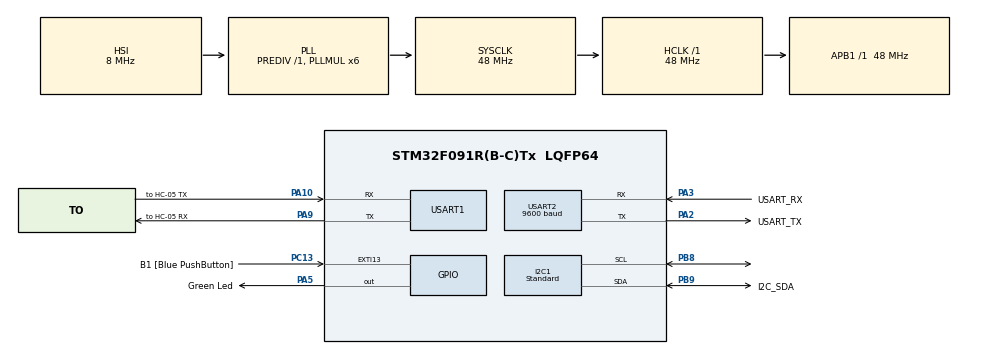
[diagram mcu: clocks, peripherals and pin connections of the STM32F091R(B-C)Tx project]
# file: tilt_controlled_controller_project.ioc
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I2C1.I2C_Speed_Mode=I2C_Standard
Mcu.Family=STM32F0
Mcu.Name=STM32F091R(B-C)Tx
Mcu.Package=LQFP64
NVIC.EXTI4_15_IRQn=true\:0\:0\:false\:false\:true\:true\:true\:true
NVIC.USART2_IRQn=true\:0\:0\:false\:false\:true\:true\:true\:true
PA10.GPIO_Label=to HC-05 TX
PA10.Mode=Asynchronous
PA10.Signal=USART1_RX
PA13.GPIO_Label=TMS
PA13.Mode=Serial_Wire
PA13.Signal=SYS_SWDIO
PA14.GPIO_Label=TCK
PA14.Mode=Serial_Wire
PA14.Signal=SYS_SWCLK
PA2.GPIO_Label=USART_TX
PA2.GPIO_Mode=GPIO_MODE_AF_PP
PA2.GPIO_PuPd=GPIO_NOPULL
PA2.GPIO_Speed=GPIO_SPEED_FREQ_LOW
PA2.Mode=Asynchronous
PA2.Signal=USART2_TX
PA3.GPIO_Label=USART_RX
PA3.GPIO_Mode=GPIO_MODE_AF_PP
PA3.GPIO_PuPd=GPIO_NOPULL
PA3.GPIO_Speed=GPIO_SPEED_FREQ_LOW
PA3.Mode=Asynchronous
PA3.Signal=USART2_RX
PA5.GPIO_Label=Green Led
PA5.GPIO_Mode=GPIO_MODE_OUTPUT_PP
PA5.GPIO_PuPd=GPIO_NOPULL
PA5.GPIO_Speed=GPIO_SPEED_FREQ_LOW
PA5.Signal=GPIO_Output
PA9.GPIO_Label=to HC-05 RX
PA9.Mode=Asynchronous
PA9.Signal=USART1_TX
PB8.Mode=I2C
PB8.Signal=I2C1_SCL
PB9.GPIO_Label=I2C_SDA
PB9.Mode=I2C
PB9.Signal=I2C1_SDA
PC13.GPIO_Label=B1 [Blue PushButton]
PC13.GPIO_ModeDefaultEXTI=GPIO_MODE_IT_FALLING
PC13.Signal=GPXTI13
PC14OSC32_IN.Mode=LSE-External-Oscillator
PC14OSC32_IN.Signal=RCC_OSC32_IN
PC15OSC32_OUT.Mode=LSE-External-Oscillator
PC15OSC32_OUT.Signal=RCC_OSC32_OUT
PF0-OSC_IN.Mode=HSE-External-Clock-Source
PF0-OSC_IN.Signal=RCC_OSC_IN
PF1-OSC_OUT.Signal=RCC_OSC_OUT
ProjectManager.HeapSize=0x200
ProjectManager.StackSize=0x400
ProjectManager.TargetToolchain=STM32CubeIDE
RCC.AHBFreq_Value=48000000
RCC.APB1Freq_Value=48000000
RCC.APB1TimFreq_Value=48000000
RCC.FLatency-AdvancedSettings=FLASH_LATENCY_1
RCC.HCLKFreq_Value=48000000
RCC.PLLMUL=RCC_PLL_MUL6
RCC.PREFETCH_ENABLE-AdvancedSettings=1
RCC.SYSCLKFreq_VALUE=48000000
RCC.SYSCLKSource=RCC_SYSCLKSOURCE_PLLCLK
USART1.VirtualMode-Asynchronous=VM_ASYNC
USART2.BaudRate=9600
USART2.VirtualMode=VM_ASYNC
USART2.VirtualMode-Asynchronous=VM_ASYNC
board=NUCLEO-F091RC

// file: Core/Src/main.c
/* USER CODE BEGIN Header */
/**
  ******************************************************************************
  * @file   main.c
  * @brief  Main program body
  * @author Anil Ozrenk
  ******************************************************************************
  * @attention
  *
  * Copyright (c) 2022 Anil Ozrenk.
  * All rights reserved.
  *
  * This software is licensed under terms that can be found in the LICENSE file
  * in the root directory of this software component.
  * If no LICENSE file comes with this software, it is provided AS-IS.
  *
  ******************************************************************************
  */
/* USER CODE END Header */
#include "main.h"

/* USER CODE BEGIN Includes */
#include "mpu6050.h"
#include "controller.h"
/* USER CODE END Includes */

/* USER CODE BEGIN PD */
#define BUFFER_LEN  13 ///< predefined lenght to main uart buffer
#define KF 0.85  	   ///< exponantial filter coeficient
/* USER CODE END PD */

I2C_HandleTypeDef hi2c1;
UART_HandleTypeDef huart1;
UART_HandleTypeDef huart2;

/* USER CODE BEGIN PV */

MPU6050_t MPU6050;
typHoverHandler hHover;
typPWMInputHandler hInput;
typPWMOutputHandler hOutput;
typVector hVector;

/// holds gyro angle
double x_angle_base;
/// holds gyro angle
double y_angle_base;
/// main rx buffer
char rx_buffer[BUFFER_LEN] = {0};
/// main tx buffer
char tx_buffer[BUFFER_LEN] = {0};
/* USER CODE END PV */

void SystemClock_Config(void);
static void MX_GPIO_Init(void);
static void MX_USART2_UART_Init(void);
static void MX_I2C1_Init(void);
static void MX_USART1_UART_Init(void);

/* USER CODE BEGIN 0 */
/**
 * external interrupt routine for base angle reset
 * gpio pin 13
 */
void HAL_GPIO_EXTI_Callback(uint16_t GPIO_Pin){
	if( GPIO_PIN_13 == GPIO_Pin){
		x_angle_base=MPU6050.KalmanAngleX;
		y_angle_base=MPU6050.KalmanAngleY;
	}
}

/* USER CODE END 0 */

int main(void)
{

  /* MCU Configuration--------------------------------------------------------*/

  /* Reset of all peripherals, Initializes the Flash interface and the Systick. */
  HAL_Init();

  /* Configure the system clock */
  SystemClock_Config();

  /* Initialize all configured peripherals */
  MX_GPIO_Init();
  MX_USART2_UART_Init();
  MX_I2C1_Init();
  MX_USART1_UART_Init();
  /* USER CODE BEGIN 2 */
  /// initialize mpu6050 module
  MPU6050_Init(&hi2c1);
  /// initialize hover struct
  hoverInit(&hHover);

  HAL_Delay(500);
  MPU6050_Read_All(&hi2c1, &MPU6050);
  /// initial x angle base
  x_angle_base=MPU6050.KalmanAngleX;
  /// initial y angle base
  y_angle_base=MPU6050.KalmanAngleY;
  /* USER CODE END 2 */

  /* Infinite loop */
  /* USER CODE BEGIN WHILE */
  while (1)
  {
	  MPU6050_Read_All(&hi2c1, &MPU6050);
	  angleToVector(&hVector, MPU6050.KalmanAngleX, x_angle_base, MPU6050.KalmanAngleY, y_angle_base, 3);
	  vectorToPwm(&hVector, &hInput);
	  pwmSmooting(&hHover,&hInput, KF);
	  command(&hHover, tx_buffer);
	  /// transmit buffer to bluetooth
	  HAL_UART_Transmit(&huart1, (uint8_t *)tx_buffer, sizeof(tx_buffer), 500);
	  /// transmit buffer via usb
	  HAL_UART_Transmit(&huart2, (uint8_t *)tx_buffer, sizeof(tx_buffer), 500);
	  char uu[]="\n\r";
	  HAL_UART_Transmit(&huart2, (uint8_t *)uu, sizeof(uu), 500);

	  HAL_Delay(20);

    /* USER CODE END WHILE */

  }
}

void SystemClock_Config(void)
{
  RCC_OscInitTypeDef RCC_OscInitStruct = {0};
  RCC_ClkInitTypeDef RCC_ClkInitStruct = {0};
  RCC_PeriphCLKInitTypeDef PeriphClkInit = {0};

  /** Initializes the RCC Oscillators according to the specified parameters
  * in the RCC_OscInitTypeDef structure.
  */
  RCC_OscInitStruct.OscillatorType = RCC_OSCILLATORTYPE_HSI;
  RCC_OscInitStruct.HSIState = RCC_HSI_ON;
  RCC_OscInitStruct.HSICalibrationValue = RCC_HSICALIBRATION_DEFAULT;
  RCC_OscInitStruct.PLL.PLLState = RCC_PLL_ON;
  RCC_OscInitStruct.PLL.PLLSource = RCC_PLLSOURCE_HSI;
  RCC_OscInitStruct.PLL.PLLMUL = RCC_PLL_MUL6;
  RCC_OscInitStruct.PLL.PREDIV = RCC_PREDIV_DIV1;
  if (HAL_RCC_OscConfig(&RCC_OscInitStruct) != HAL_OK)
  {
    Error_Handler();
  }

  /** Initializes the CPU, AHB and APB buses clocks
  */
  RCC_ClkInitStruct.ClockType = RCC_CLOCKTYPE_HCLK|RCC_CLOCKTYPE_SYSCLK
                              |RCC_CLOCKTYPE_PCLK1;
  RCC_ClkInitStruct.SYSCLKSource = RCC_SYSCLKSOURCE_PLLCLK;
  RCC_ClkInitStruct.AHBCLKDivider = RCC_SYSCLK_DIV1;
  RCC_ClkInitStruct.APB1CLKDivider = RCC_HCLK_DIV1;

  if (HAL_RCC_ClockConfig(&RCC_ClkInitStruct, FLASH_LATENCY_1) != HAL_OK)
  {
    Error_Handler();
  }
  PeriphClkInit.PeriphClockSelection = RCC_PERIPHCLK_USART1|RCC_PERIPHCLK_USART2
                              |RCC_PERIPHCLK_I2C1;
  PeriphClkInit.Usart1ClockSelection = RCC_USART1CLKSOURCE_PCLK1;
  PeriphClkInit.Usart2ClockSelection = RCC_USART2CLKSOURCE_PCLK1;
  PeriphClkInit.I2c1ClockSelection = RCC_I2C1CLKSOURCE_HSI;
  if (HAL_RCCEx_PeriphCLKConfig(&PeriphClkInit) != HAL_OK)
  {
    Error_Handler();
  }
}

static void MX_I2C1_Init(void)
{

  hi2c1.Instance = I2C1;
  hi2c1.Init.Timing = 0x2000090E;
  hi2c1.Init.OwnAddress1 = 0;
  hi2c1.Init.AddressingMode = I2C_ADDRESSINGMODE_7BIT;
  hi2c1.Init.DualAddressMode = I2C_DUALADDRESS_DISABLE;
  hi2c1.Init.OwnAddress2 = 0;
  hi2c1.Init.OwnAddress2Masks = I2C_OA2_NOMASK;
  hi2c1.Init.GeneralCallMode = I2C_GENERALCALL_DISABLE;
  hi2c1.Init.NoStretchMode = I2C_NOSTRETCH_DISABLE;
  if (HAL_I2C_Init(&hi2c1) != HAL_OK)
  {
    Error_Handler();
  }

  /** Configure Analogue filter
  */
  if (HAL_I2CEx_ConfigAnalogFilter(&hi2c1, I2C_ANALOGFILTER_ENABLE) != HAL_OK)
  {
    Error_Handler();
  }

  /** Configure Digital filter
  */
  if (HAL_I2CEx_ConfigDigitalFilter(&hi2c1, 0) != HAL_OK)
  {
    Error_Handler();
  }

}

static void MX_USART1_UART_Init(void)
{

  huart1.Instance = USART1;
  huart1.Init.BaudRate = 9600;
  huart1.Init.WordLength = UART_WORDLENGTH_8B;
  huart1.Init.StopBits = UART_STOPBITS_1;
  huart1.Init.Parity = UART_PARITY_NONE;
  huart1.Init.Mode = UART_MODE_TX_RX;
  huart1.Init.HwFlowCtl = UART_HWCONTROL_NONE;
  huart1.Init.OverSampling = UART_OVERSAMPLING_16;
  huart1.Init.OneBitSampling = UART_ONE_BIT_SAMPLE_DISABLE;
  huart1.AdvancedInit.AdvFeatureInit = UART_ADVFEATURE_NO_INIT;
  if (HAL_UART_Init(&huart1) != HAL_OK)
  {
    Error_Handler();
  }

}

static void MX_USART2_UART_Init(void)
{

  huart2.Instance = USART2;
  huart2.Init.BaudRate = 9600;
  huart2.Init.WordLength = UART_WORDLENGTH_8B;
  huart2.Init.StopBits = UART_STOPBITS_1;
  huart2.Init.Parity = UART_PARITY_NONE;
  huart2.Init.Mode = UART_MODE_TX_RX;
  huart2.Init.HwFlowCtl = UART_HWCONTROL_NONE;
  huart2.Init.OverSampling = UART_OVERSAMPLING_16;
  huart2.Init.OneBitSampling = UART_ONE_BIT_SAMPLE_DISABLE;
  huart2.AdvancedInit.AdvFeatureInit = UART_ADVFEATURE_NO_INIT;
  if (HAL_UART_Init(&huart2) != HAL_OK)
  {
    Error_Handler();
  }

}

static void MX_GPIO_Init(void)
{
  GPIO_InitTypeDef GPIO_InitStruct = {0};

  /* GPIO Ports Clock Enable */
  __HAL_RCC_GPIOC_CLK_ENABLE();
  __HAL_RCC_GPIOF_CLK_ENABLE();
  __HAL_RCC_GPIOA_CLK_ENABLE();
  __HAL_RCC_GPIOB_CLK_ENABLE();

  /*Configure GPIO pin Output Level */
  HAL_GPIO_WritePin(LD2_GPIO_Port, LD2_Pin, GPIO_PIN_RESET);

  /*Configure GPIO pin : B1_Pin */
  GPIO_InitStruct.Pin = B1_Pin;
  GPIO_InitStruct.Mode = GPIO_MODE_IT_FALLING;
  GPIO_InitStruct.Pull = GPIO_NOPULL;
  HAL_GPIO_Init(B1_GPIO_Port, &GPIO_InitStruct);

  /*Configure GPIO pin : LD2_Pin */
  GPIO_InitStruct.Pin = LD2_Pin;
  GPIO_InitStruct.Mode = GPIO_MODE_OUTPUT_PP;
  GPIO_InitStruct.Pull = GPIO_NOPULL;
  GPIO_InitStruct.Speed = GPIO_SPEED_FREQ_LOW;
  HAL_GPIO_Init(LD2_GPIO_Port, &GPIO_InitStruct);

  /* EXTI interrupt init*/
  HAL_NVIC_SetPriority(EXTI4_15_IRQn, 0, 0);
  HAL_NVIC_EnableIRQ(EXTI4_15_IRQn);

}

void Error_Handler(void)
{
  __disable_irq();
  while (1)
  {
  }
}
